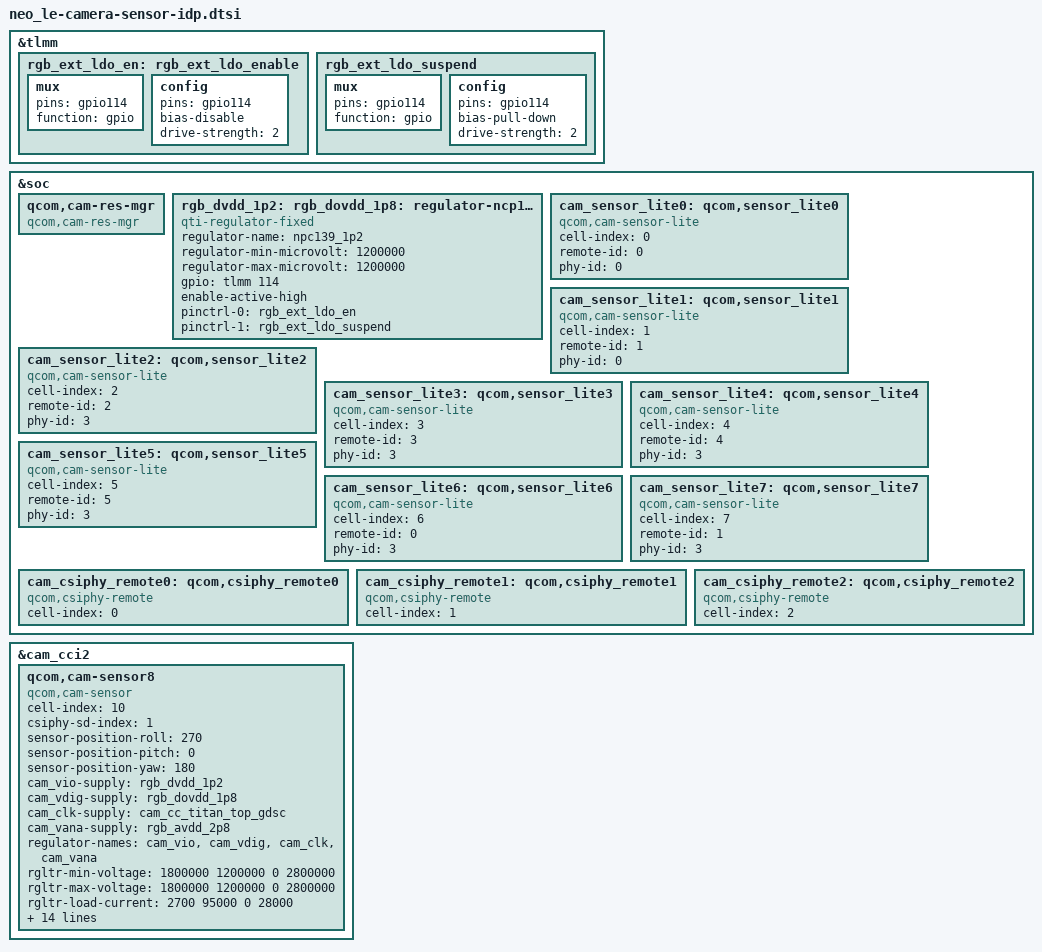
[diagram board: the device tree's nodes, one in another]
#include <dt-bindings/clock/qcom,camcc-neo.h>
#include <dt-bindings/msm-camera.h>

&tlmm {
	rgb_ext_ldo_en: rgb_ext_ldo_enable {
		mux {
			pins = "gpio114"; // Only 2
			function = "gpio";
		};

		config {
			pins = "gpio114";
			bias-disable; /* No PULL */
			drive-strength = <2>; /* 2 MA */
		};
	};

	rgb_ext_ldo_suspend: rgb_ext_ldo_suspend {
		mux {
			pins = "gpio114"; // Only 2
			function = "gpio";
		};

		config {
			pins = "gpio114";
			bias-pull-down; /* PULL DOWN */
			drive-strength = <2>; /* 2 MA */
		};
	};
};

&soc {

	qcom,cam-res-mgr {
		compatible = "qcom,cam-res-mgr";
		status = "ok";
	};

	rgb_dvdd_1p2: rgb_dovdd_1p8:
	rgb_avdd_2p8: regulator-ncp139_1p2 {
		compatible = "qti-regulator-fixed";
		regulator-name = "npc139_1p2";
		regulator-min-microvolt = <1200000>;
		regulator-max-microvolt = <1200000>;
		gpio = <&tlmm 114 0>;
		enable-active-high;
		pinctrl-names = "default", "suspend";
		pinctrl-0 = <&rgb_ext_ldo_en>;
		pinctrl-1 = <&rgb_ext_ldo_suspend>;
	};

	cam_sensor_lite0: qcom,sensor_lite0 {
		cell-index = <0>;
		remote-id  = <0>;
		phy-id     = <0>;
		compatible = "qcom,cam-sensor-lite";
		status = "ok";
	};

	cam_sensor_lite1: qcom,sensor_lite1 {
		cell-index = <1>;
		remote-id  = <1>;
		phy-id     = <0>;
		compatible = "qcom,cam-sensor-lite";
		status = "ok";
	};

	cam_sensor_lite2: qcom,sensor_lite2 {
		cell-index = <2>;
		remote-id  = <2>;
		phy-id     = <3>;
		compatible = "qcom,cam-sensor-lite";
		status = "ok";
	};

	cam_sensor_lite3: qcom,sensor_lite3 {
		cell-index = <3>;
		remote-id  = <3>;
		phy-id     = <3>;
		compatible = "qcom,cam-sensor-lite";
		status = "ok";
	};

	cam_sensor_lite4: qcom,sensor_lite4 {
		cell-index = <4>;
		remote-id  = <4>;
		phy-id     = <3>;
		compatible = "qcom,cam-sensor-lite";
		status = "ok";
	};

	cam_sensor_lite5: qcom,sensor_lite5 {
		cell-index = <5>;
		remote-id  = <5>;
		phy-id     = <3>;
		compatible = "qcom,cam-sensor-lite";
		status = "ok";
	};

	cam_sensor_lite6: qcom,sensor_lite6 {
		cell-index = <6>;
		remote-id  = <0>;
		phy-id     = <3>;
		compatible = "qcom,cam-sensor-lite";
		status = "ok";
	};

	cam_sensor_lite7: qcom,sensor_lite7 {
		cell-index = <7>;
		remote-id  = <1>;
		phy-id     = <3>;
		compatible = "qcom,cam-sensor-lite";
		status = "ok";
	};

	cam_csiphy_remote0: qcom,csiphy_remote0 {
		cell-index = <0>;
		compatible = "qcom,csiphy-remote", "qcom,csiphy-remote-v1.2.1";
		status = "ok";
	};

	cam_csiphy_remote1: qcom,csiphy_remote1 {
		cell-index = <1>;
		compatible = "qcom,csiphy-remote", "qcom,csiphy-remote-v1.2.1";
		status = "ok";
	};

	cam_csiphy_remote2: qcom,csiphy_remote2 {
		cell-index = <2>;
		compatible = "qcom,csiphy-remote", "qcom,csiphy-remote-v1.2.1";
		status = "ok";
	};
};

&cam_cci2 {
	qcom,cam-sensor8 {
		cell-index = <10>;
		compatible = "qcom,cam-sensor";
		csiphy-sd-index = <1>;
		sensor-position-roll = <270>;
		sensor-position-pitch = <0>;
		sensor-position-yaw = <180>;
		cam_vio-supply  = <&rgb_dvdd_1p2>;
		cam_vdig-supply = <&rgb_dovdd_1p8>;
		cam_clk-supply  = <&cam_cc_titan_top_gdsc>;
		cam_vana-supply = <&rgb_avdd_2p8>;
		regulator-names = "cam_vio", "cam_vdig",
			"cam_clk", "cam_vana";
		rgltr-min-voltage  = <1800000 1200000 0 2800000>;
		rgltr-max-voltage  = <1800000 1200000 0 2800000>;
		rgltr-load-current = <2700 95000 0 28000>;
		gpio-no-mux = <0>;
		pinctrl-names = "cam_default", "cam_suspend";
		pinctrl-0 = <&cam_sensor_mclk0_active
			&cam_sensor_active_rst0>;
		pinctrl-1 = <&cam_sensor_mclk0_suspend
			&cam_sensor_suspend_rst0>;
		gpios = <&tlmm 69 0>,
			<&tlmm 65 0>;
		gpio-reset = <1>;
		gpio-req-tbl-num = <0 1>;
		gpio-req-tbl-flags = <1 0>;
		gpio-req-tbl-label = "CAMIF_MCLK0",
					"CAM_RESET0";
		cci-master = <0>;
		clocks = <&camcc CAM_CC_MCLK0_CLK>;
		clock-names = "cam_clk";
		clock-cntl-level = "nominal";
		clock-rates = <24000000>;
		status = "ok";
	};
};

